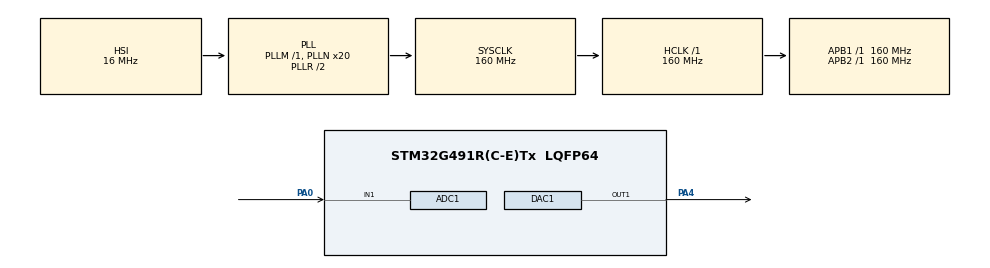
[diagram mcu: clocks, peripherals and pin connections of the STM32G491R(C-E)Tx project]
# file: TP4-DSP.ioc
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ADC1.Channel-0\#ChannelRegularConversion=ADC_CHANNEL_1
ADC1.NbrOfConversionFlag=1
ADC1.OffsetNumber-0\#ChannelRegularConversion=ADC_OFFSET_NONE
ADC1.Rank-0\#ChannelRegularConversion=1
ADC1.SamplingTime-0\#ChannelRegularConversion=ADC_SAMPLETIME_2CYCLES_5
ADC1.master=1
Mcu.Family=STM32G4
Mcu.Name=STM32G491R(C-E)Tx
Mcu.Package=LQFP64
NUCLEO-G491RE.BUTTON=1
NUCLEO-G491RE.LD2=true
NUCLEO-G491RE.VCP=true
NVIC.ADC1_2_IRQn=true\:0\:0\:false\:false\:true\:true\:true\:true
NVIC.EXTI15_10_IRQn=true\:0\:0\:false\:false\:true\:false\:true\:true
NVIC.PriorityGroup=NVIC_PRIORITYGROUP_4
NVIC.TIM2_IRQn=true\:0\:0\:false\:false\:true\:true\:true\:true
PA0.Mode=IN1-Single-Ended
PA0.Signal=ADC1_IN1
PA13.GPIO_Label=T_SWDIO
PA13.Mode=Serial_Wire
PA13.Signal=SYS_JTMS-SWDIO
PA14.GPIO_Label=T_SWCLK
PA14.Mode=Serial_Wire
PA14.Signal=SYS_JTCK-SWCLK
PA2.Signal=LPUART1_TX
PA3.Signal=LPUART1_RX
PA4.Signal=COMP_DAC11_group
PB3.GPIO_Label=T_SWO
PB3.Signal=SYS_JTDO-SWO
PC14-OSC32_IN.GPIO_Label=RCC_OSC32_IN
PC14-OSC32_IN.Signal=RCC_OSC32_IN
PC15-OSC32_OUT.GPIO_Label=RCC_OSC32_OUT
PC15-OSC32_OUT.Signal=RCC_OSC32_OUT
PF0-OSC_IN.GPIO_Label=RCC_OSC_IN
PF0-OSC_IN.Signal=RCC_OSC_IN
PF1-OSC_OUT.GPIO_Label=RCC_OSC_OUT
PF1-OSC_OUT.Signal=RCC_OSC_OUT
ProjectManager.HeapSize=0x200
ProjectManager.StackSize=0x400
ProjectManager.TargetToolchain=STM32CubeIDE
RCC.ADC12Freq_Value=160000000
RCC.ADC345Freq_Value=160000000
RCC.AHBFreq_Value=160000000
RCC.APB1Freq_Value=160000000
RCC.APB1TimFreq_Value=160000000
RCC.APB2Freq_Value=160000000
RCC.APB2TimFreq_Value=160000000
RCC.CortexFreq_Value=160000000
RCC.EXTERNAL_CLOCK_VALUE=12288000
RCC.HCLKFreq_Value=160000000
RCC.HSE_VALUE=24000000
RCC.HSI48_VALUE=48000000
RCC.HSI_VALUE=16000000
RCC.LSE_VALUE=32768
RCC.PLLN=20
RCC.RTCClockSelection=RCC_RTCCLKSOURCE_LSE
RCC.SYSCLKFreq_VALUE=160000000
RCC.SYSCLKSource=RCC_SYSCLKSOURCE_PLLCLK
RCC.USBFreq_Value=48000000
RCC.VCOOutputFreq_Value=320000000
SH.COMP_DAC11_group.0=DAC1_OUT1,DAC_OUT1
TIM2.PeriodNoDither=16999
TIM2.Prescaler=0
VP_NUCLEO-G491RE_VS_BSP_COMMON.Mode=COMMON
VP_SYS_VS_DBSignals.Mode=DisableDeadBatterySignals
VP_TIM2_VS_ClockSourceINT.Mode=Internal
board=NUCLEO-G491RE

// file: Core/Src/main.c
/* USER CODE BEGIN Header */
/**
  ******************************************************************************
  * @file           : main.c
  * @brief          : Main program body
  ******************************************************************************
  * @attention
  *
  * Copyright (c) 2026 STMicroelectronics.
  * All rights reserved.
  *
  * This software is licensed under terms that can be found in the LICENSE file
  * in the root directory of this software component.
  * If no LICENSE file comes with this software, it is provided AS-IS.
  *
  ******************************************************************************
  */
/* USER CODE END Header */
#include "main.h"

COM_InitTypeDef BspCOMInit;
ADC_HandleTypeDef hadc1;

DAC_HandleTypeDef hdac1;

TIM_HandleTypeDef htim2;

/* USER CODE BEGIN PV */

 uint16_t dac_value = 0;
 uint16_t dac_buffer[1000] = {0};

/* USER CODE END PV */

void SystemClock_Config(void);
static void MX_GPIO_Init(void);
static void MX_ADC1_Init(void);
static void MX_DAC1_Init(void);
static void MX_TIM2_Init(void);

int main(void)
{

  /* MCU Configuration--------------------------------------------------------*/

  /* Reset of all peripherals, Initializes the Flash interface and the Systick. */
  HAL_Init();

  /* Configure the system clock */
  SystemClock_Config();

  /* Initialize all configured peripherals */
  MX_GPIO_Init();
  MX_ADC1_Init();
  MX_DAC1_Init();
  MX_TIM2_Init();
  /* USER CODE BEGIN 2 */

  HAL_TIM_Base_Start_IT(&htim2);
  HAL_DAC_Start(&hdac1, DAC1_CHANNEL_2);

  /* USER CODE END 2 */

  /* Initialize led */
  BSP_LED_Init(LED_GREEN);

  /* Initialize USER push-button, will be used to trigger an interrupt each time it's pressed.*/
  BSP_PB_Init(BUTTON_USER, BUTTON_MODE_EXTI);

  /* Initialize COM1 port (115200, 8 bits (7-bit data + 1 stop bit), no parity */
  BspCOMInit.BaudRate   = 115200;
  BspCOMInit.WordLength = COM_WORDLENGTH_8B;
  BspCOMInit.StopBits   = COM_STOPBITS_1;
  BspCOMInit.Parity     = COM_PARITY_NONE;
  BspCOMInit.HwFlowCtl  = COM_HWCONTROL_NONE;
  if (BSP_COM_Init(COM1, &BspCOMInit) != BSP_ERROR_NONE)
  {
    Error_Handler();
  }

  /* Infinite loop */
  while (1)
  {

  }
}

void SystemClock_Config(void)
{
  RCC_OscInitTypeDef RCC_OscInitStruct = {0};
  RCC_ClkInitTypeDef RCC_ClkInitStruct = {0};

  /** Configure the main internal regulator output voltage
  */
  HAL_PWREx_ControlVoltageScaling(PWR_REGULATOR_VOLTAGE_SCALE1_BOOST);

  /** Initializes the RCC Oscillators according to the specified parameters
  * in the RCC_OscInitTypeDef structure.
  */
  RCC_OscInitStruct.OscillatorType = RCC_OSCILLATORTYPE_HSI;
  RCC_OscInitStruct.HSIState = RCC_HSI_ON;
  RCC_OscInitStruct.HSICalibrationValue = RCC_HSICALIBRATION_DEFAULT;
  RCC_OscInitStruct.PLL.PLLState = RCC_PLL_ON;
  RCC_OscInitStruct.PLL.PLLSource = RCC_PLLSOURCE_HSI;
  RCC_OscInitStruct.PLL.PLLM = RCC_PLLM_DIV1;
  RCC_OscInitStruct.PLL.PLLN = 20;
  RCC_OscInitStruct.PLL.PLLP = RCC_PLLP_DIV2;
  RCC_OscInitStruct.PLL.PLLQ = RCC_PLLQ_DIV2;
  RCC_OscInitStruct.PLL.PLLR = RCC_PLLR_DIV2;
  if (HAL_RCC_OscConfig(&RCC_OscInitStruct) != HAL_OK)
  {
    Error_Handler();
  }

  /** Initializes the CPU, AHB and APB buses clocks
  */
  RCC_ClkInitStruct.ClockType = RCC_CLOCKTYPE_HCLK|RCC_CLOCKTYPE_SYSCLK
                              |RCC_CLOCKTYPE_PCLK1|RCC_CLOCKTYPE_PCLK2;
  RCC_ClkInitStruct.SYSCLKSource = RCC_SYSCLKSOURCE_PLLCLK;
  RCC_ClkInitStruct.AHBCLKDivider = RCC_SYSCLK_DIV1;
  RCC_ClkInitStruct.APB1CLKDivider = RCC_HCLK_DIV1;
  RCC_ClkInitStruct.APB2CLKDivider = RCC_HCLK_DIV1;

  if (HAL_RCC_ClockConfig(&RCC_ClkInitStruct, FLASH_LATENCY_4) != HAL_OK)
  {
    Error_Handler();
  }
}

static void MX_ADC1_Init(void)
{

  ADC_MultiModeTypeDef multimode = {0};
  ADC_ChannelConfTypeDef sConfig = {0};

  /** Common config
  */
  hadc1.Instance = ADC1;
  hadc1.Init.ClockPrescaler = ADC_CLOCK_SYNC_PCLK_DIV4;
  hadc1.Init.Resolution = ADC_RESOLUTION_12B;
  hadc1.Init.DataAlign = ADC_DATAALIGN_RIGHT;
  hadc1.Init.GainCompensation = 0;
  hadc1.Init.ScanConvMode = ADC_SCAN_DISABLE;
  hadc1.Init.EOCSelection = ADC_EOC_SINGLE_CONV;
  hadc1.Init.LowPowerAutoWait = DISABLE;
  hadc1.Init.ContinuousConvMode = DISABLE;
  hadc1.Init.NbrOfConversion = 1;
  hadc1.Init.DiscontinuousConvMode = DISABLE;
  hadc1.Init.ExternalTrigConv = ADC_SOFTWARE_START;
  hadc1.Init.ExternalTrigConvEdge = ADC_EXTERNALTRIGCONVEDGE_NONE;
  hadc1.Init.DMAContinuousRequests = DISABLE;
  hadc1.Init.Overrun = ADC_OVR_DATA_PRESERVED;
  hadc1.Init.OversamplingMode = DISABLE;
  if (HAL_ADC_Init(&hadc1) != HAL_OK)
  {
    Error_Handler();
  }

  /** Configure the ADC multi-mode
  */
  multimode.Mode = ADC_MODE_INDEPENDENT;
  if (HAL_ADCEx_MultiModeConfigChannel(&hadc1, &multimode) != HAL_OK)
  {
    Error_Handler();
  }

  /** Configure Regular Channel
  */
  sConfig.Channel = ADC_CHANNEL_1;
  sConfig.Rank = ADC_REGULAR_RANK_1;
  sConfig.SamplingTime = ADC_SAMPLETIME_2CYCLES_5;
  sConfig.SingleDiff = ADC_SINGLE_ENDED;
  sConfig.OffsetNumber = ADC_OFFSET_NONE;
  sConfig.Offset = 0;
  if (HAL_ADC_ConfigChannel(&hadc1, &sConfig) != HAL_OK)
  {
    Error_Handler();
  }

}

static void MX_DAC1_Init(void)
{

  DAC_ChannelConfTypeDef sConfig = {0};

  /** DAC Initialization
  */
  hdac1.Instance = DAC1;
  if (HAL_DAC_Init(&hdac1) != HAL_OK)
  {
    Error_Handler();
  }

  /** DAC channel OUT1 config
  */
  sConfig.DAC_HighFrequency = DAC_HIGH_FREQUENCY_INTERFACE_MODE_AUTOMATIC;
  sConfig.DAC_DMADoubleDataMode = DISABLE;
  sConfig.DAC_SignedFormat = DISABLE;
  sConfig.DAC_SampleAndHold = DAC_SAMPLEANDHOLD_DISABLE;
  sConfig.DAC_Trigger = DAC_TRIGGER_NONE;
  sConfig.DAC_Trigger2 = DAC_TRIGGER_NONE;
  sConfig.DAC_OutputBuffer = DAC_OUTPUTBUFFER_ENABLE;
  sConfig.DAC_ConnectOnChipPeripheral = DAC_CHIPCONNECT_EXTERNAL;
  sConfig.DAC_UserTrimming = DAC_TRIMMING_FACTORY;
  if (HAL_DAC_ConfigChannel(&hdac1, &sConfig, DAC_CHANNEL_1) != HAL_OK)
  {
    Error_Handler();
  }

}

static void MX_TIM2_Init(void)
{

  TIM_ClockConfigTypeDef sClockSourceConfig = {0};
  TIM_MasterConfigTypeDef sMasterConfig = {0};

  htim2.Instance = TIM2;
  htim2.Init.Prescaler = 0;
  htim2.Init.CounterMode = TIM_COUNTERMODE_UP;
  htim2.Init.Period = 19999;
  htim2.Init.ClockDivision = TIM_CLOCKDIVISION_DIV1;
  htim2.Init.AutoReloadPreload = TIM_AUTORELOAD_PRELOAD_DISABLE;
  if (HAL_TIM_Base_Init(&htim2) != HAL_OK)
  {
    Error_Handler();
  }
  sClockSourceConfig.ClockSource = TIM_CLOCKSOURCE_INTERNAL;
  if (HAL_TIM_ConfigClockSource(&htim2, &sClockSourceConfig) != HAL_OK)
  {
    Error_Handler();
  }
  sMasterConfig.MasterOutputTrigger = TIM_TRGO_RESET;
  sMasterConfig.MasterSlaveMode = TIM_MASTERSLAVEMODE_DISABLE;
  if (HAL_TIMEx_MasterConfigSynchronization(&htim2, &sMasterConfig) != HAL_OK)
  {
    Error_Handler();
  }

}

static void MX_GPIO_Init(void)
{

  /* GPIO Ports Clock Enable */
  __HAL_RCC_GPIOC_CLK_ENABLE();
  __HAL_RCC_GPIOF_CLK_ENABLE();
  __HAL_RCC_GPIOA_CLK_ENABLE();
  __HAL_RCC_GPIOB_CLK_ENABLE();

}

/* USER CODE BEGIN 4 */

void HAL_ADC_ConvCpltCallback(ADC_HandleTypeDef *hadc){

//  dac_value = HAL_ADC_GetValue(hadc); Sin ganancia
//	dac_value = 2 * HAL_ADC_GetValue(hadc); //Con ganancia
//	dac_value = 5000 + HAL_ADC_GetValue(hadc);

	for (int i = 1; i < 1000; ++i) {

		dac_buffer[i]=dac_buffer[i-1];

	}

	dac_buffer[0] = HAL_ADC_GetValue(hadc);

	dac_value = dac_buffer[999];

	HAL_DAC_SetValue ( & hdac1 , DAC_CHANNEL_1 , DAC_ALIGN_12B_R , dac_value ); //le asigno valor
	HAL_DAC_Start ( & hdac1 , DAC_CHANNEL_1 ); //Pongo a convertir.

}

void HAL_TIM_PeriodElapsedCallback(TIM_HandleTypeDef *htim) {

	if (htim->Instance == TIM2) {

		HAL_ADC_Start_IT(&hadc1); //arranco a convertir y habilito interrupción

	}

}

/* USER CODE END 4 */

void Error_Handler(void)
{
  __disable_irq();
  while (1)
  {
  }
}
